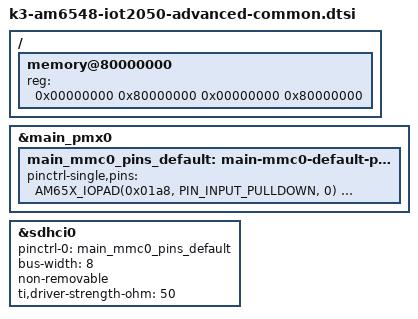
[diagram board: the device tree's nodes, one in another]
// SPDX-License-Identifier: GPL-2.0-only
/*
 * Copyright (c) Siemens AG, 2018-2021
 *
 * Authors:
 *   Le Jin <le.jin@siemens.com>
 *   Jan Kiszka <jan.kiszka@siemens.com>
 *
 * Common bits of the IOT2050 Advanced variant, PG1 and PG2
 */

/dts-v1/;

#include "k3-am654.dtsi"
#include "k3-am65-iot2050-common.dtsi"

/ {
	memory@80000000 {
		device_type = "memory";
		/* 2G RAM */
		reg = <0x00000000 0x80000000 0x00000000 0x80000000>;
	};
};

&main_pmx0 {
	main_mmc0_pins_default: main-mmc0-default-pins {
		pinctrl-single,pins = <
			AM65X_IOPAD(0x01a8, PIN_INPUT_PULLDOWN, 0)  /* (B25) MMC0_CLK */
			AM65X_IOPAD(0x01ac, PIN_INPUT_PULLUP,   0)  /* (B27) MMC0_CMD */
			AM65X_IOPAD(0x01a4, PIN_INPUT_PULLUP,   0)  /* (A26) MMC0_DAT0 */
			AM65X_IOPAD(0x01a0, PIN_INPUT_PULLUP,   0)  /* (E25) MMC0_DAT1 */
			AM65X_IOPAD(0x019c, PIN_INPUT_PULLUP,   0)  /* (C26) MMC0_DAT2 */
			AM65X_IOPAD(0x0198, PIN_INPUT_PULLUP,   0)  /* (A25) MMC0_DAT3 */
			AM65X_IOPAD(0x0194, PIN_INPUT_PULLUP,   0)  /* (E24) MMC0_DAT4 */
			AM65X_IOPAD(0x0190, PIN_INPUT_PULLUP,   0)  /* (A24) MMC0_DAT5 */
			AM65X_IOPAD(0x018c, PIN_INPUT_PULLUP,   0)  /* (B26) MMC0_DAT6 */
			AM65X_IOPAD(0x0188, PIN_INPUT_PULLUP,   0)  /* (D25) MMC0_DAT7 */
			AM65X_IOPAD(0x01b8, PIN_OUTPUT_PULLUP,  7)  /* (B23) MMC0_SDWP */
			AM65X_IOPAD(0x01b4, PIN_INPUT_PULLUP,   0)  /* (A23) MMC0_SDCD */
			AM65X_IOPAD(0x01b0, PIN_INPUT,          0)  /* (C25) MMC0_DS */
		>;
	};
};

/* eMMC */
&sdhci0 {
	status = "okay";
	pinctrl-names = "default";
	pinctrl-0 = <&main_mmc0_pins_default>;
	bus-width = <8>;
	non-removable;
	ti,driver-strength-ohm = <50>;
};
